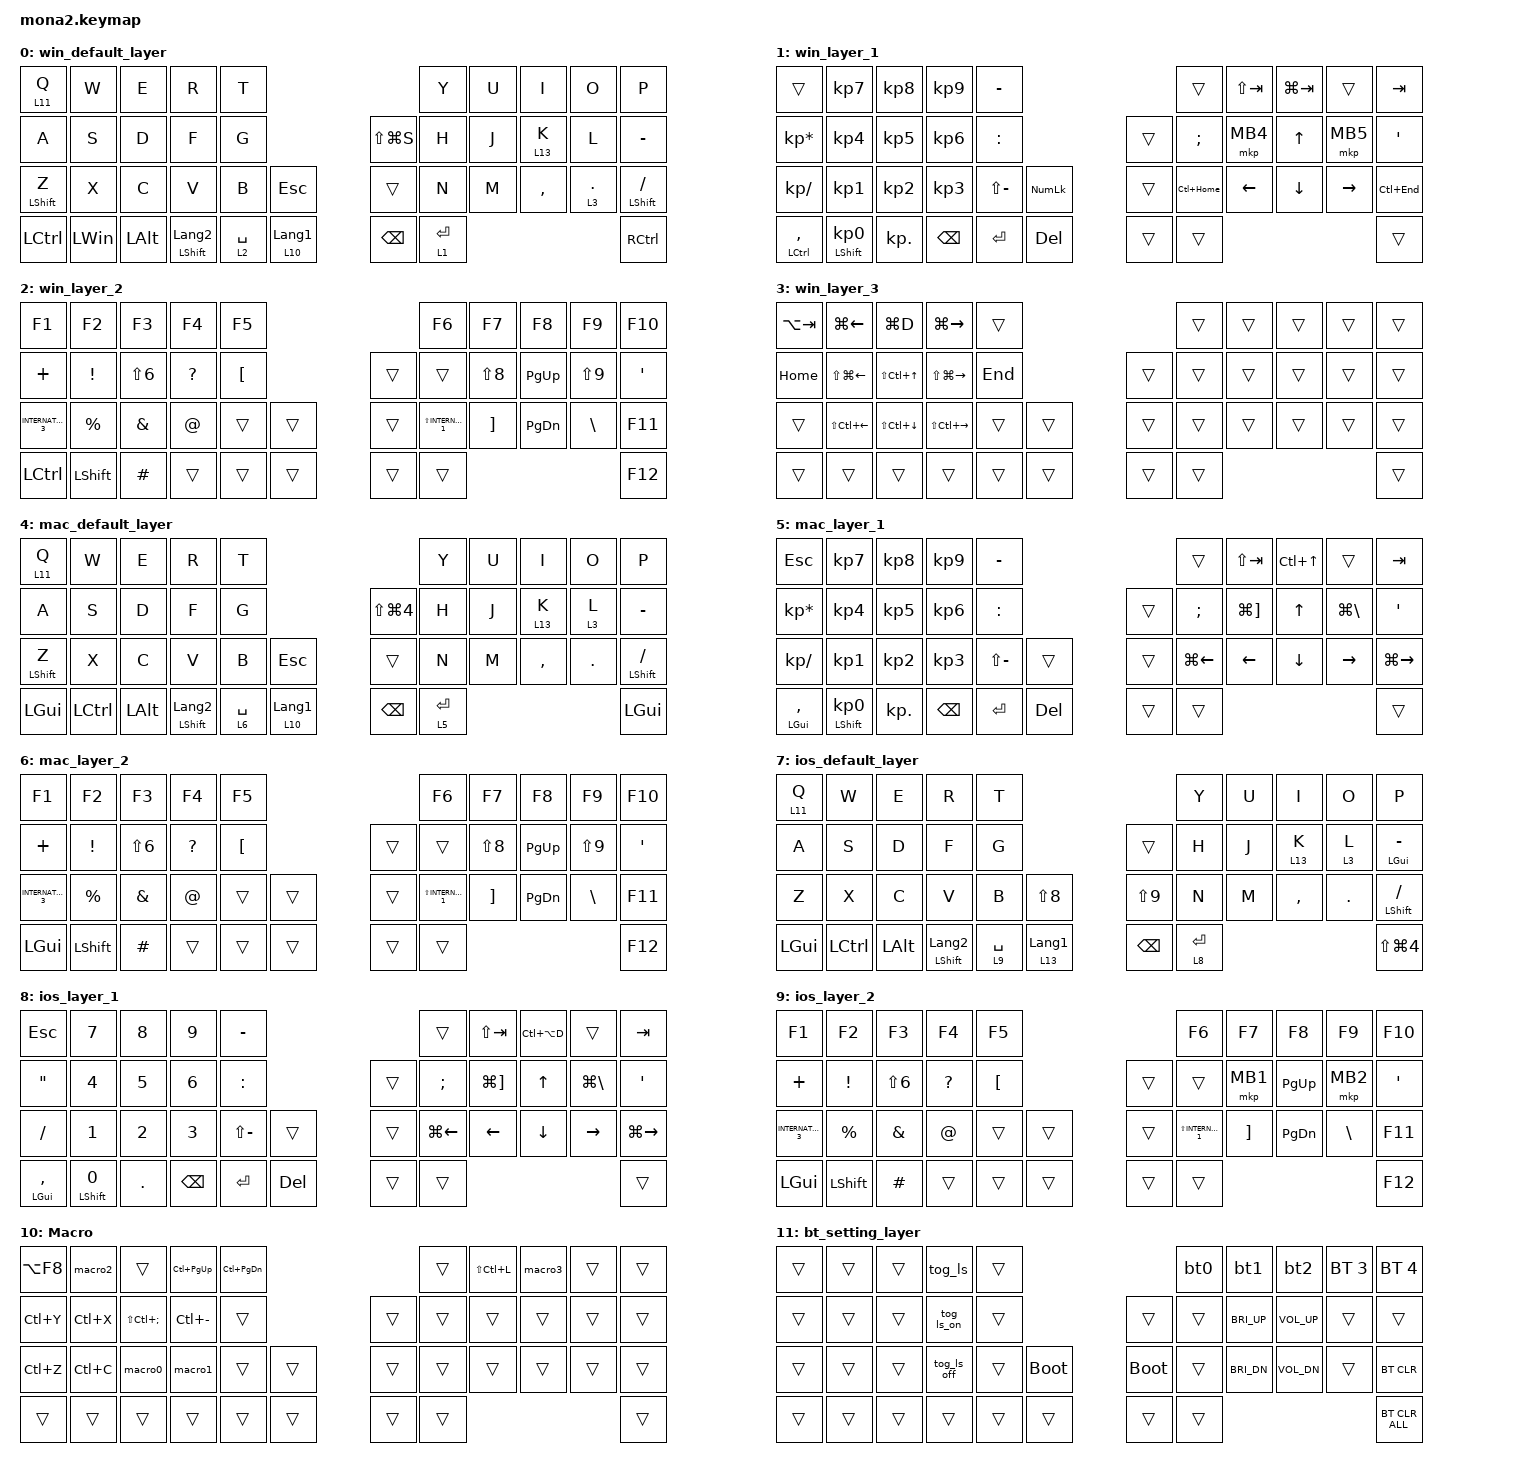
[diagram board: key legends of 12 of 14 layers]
#include <input/processors.dtsi>
#include <dt-bindings/zmk/input_transform.h>
#include <zephyr/dt-bindings/input/input-event-codes.h>
#include <behaviors.dtsi>
#include <dt-bindings/zmk/bt.h>
#include <dt-bindings/zmk/keys.h>
#include <dt-bindings/zmk/pointing.h>

#define ZMK_POINTING_DEFAULT_SCRL_VAL 100
#define MOUSE 12
#define SCROLL 13

&mt {
    flavor = "balanced";
    quick-tap-ms = <0>;
};

&lt {
    quick-tap-ms = <0>; // 初期設定は300
    flavor = "balanced";
};

&mkp_input_listener { input-processors = <&zip_temp_layer 12 250>; };

/ {
    combos {
        compatible = "zmk,combos";

        alt+ctrl+del {
            bindings = <&kp LA(LC(DELETE))>;
            key-positions = <9 40>;
        };

        left_click {
            bindings = <&mkp LCLK>;
            key-positions = <18 17>;
        };

        right_click {
            bindings = <&mkp RCLK>;
            key-positions = <19 18>;
        };

        caps_word {
            bindings = <&caps_word>;
            key-positions = <38 39>;
        };
    };

    macros {
        to_layer_0: to_layer_0 {
            compatible = "zmk,behavior-macro-one-param";
            #binding-cells = <1>;
            bindings = <&to 0 &macro_param_1to1 &kp MACRO_PLACEHOLDER>;
            label = "TO_LAYER_0";
        };

        macro0: macro0 {
            compatible = "zmk,behavior-macro";
            #binding-cells = <0>;
            bindings = <&kp LA(LC(V)) &kp V &kp ENTER>;
            label = "MACRO0";
        };

        macro1: macro1 {
            compatible = "zmk,behavior-macro";
            #binding-cells = <0>;
            bindings = <&kp LA(H) &kp M &kp C &kp ENTER>;
            label = "MACRO1";
        };

        macro2: macro2 {
            compatible = "zmk,behavior-macro";
            #binding-cells = <0>;
            bindings = <&kp LC(G) &kp LA(S) &kp K &kp ENTER>;
            label = "MACRO2";
        };

        macro3: macro3 {
            compatible = "zmk,behavior-macro";
            #binding-cells = <0>;
            bindings = <&kp LEFT_ALT &kp D &kp F &kp S>;
            label = "MACRO3";
        };

        macro4_copy_lay15: macro_4 {
            compatible = "zmk,behavior-macro";
            #binding-cells = <0>;
            bindings = <&kp LS(LC(DOWN_ARROW)) &kp LS(LC(RIGHT_ARROW)) &kp LS(LC(RIGHT_ARROW)) &kp LC(C)>;
            label = "MACRO_4";
        };

        macro_5_copy_lay15: macro_5 {
            compatible = "zmk,behavior-macro";
            #binding-cells = <0>;
            bindings = <&kp LS(LC(RIGHT_ARROW)) &kp LS(LC(RIGHT_ARROW)) &kp LC(C)>;
            label = "MACRO_5";
        };

        macro_6_ketsugou_lay15: macro_6 {
            compatible = "zmk,behavior-macro";
            #binding-cells = <0>;
            bindings = <&kp LS(LC(DOWN_ARROW)) &kp LA(H) &kp M &kp C &kp ENTER>;
            label = "MACRO_6";
        };

        bt0: bt0 {
            compatible = "zmk,behavior-macro";
            #binding-cells = <0>;
            bindings =
                <&tog_off 4 &tog_off 7>,
                <&macro_wait_time 200>,
                <&bt BT_SEL 0>,
                <&macro_wait_time 500>,
                <&tog_on 0 &bt BT_DISC 1 &bt BT_DISC 2>;

            label = "BT0";
        };

        bt1: bt1 {
            compatible = "zmk,behavior-macro";
            #binding-cells = <0>;
            bindings =
                <&tog_off 0 &tog_off 4 &tog_off 7>,
                <&macro_wait_time 200>,
                <&bt BT_SEL 1>,
                <&macro_wait_time 500>,
                <&tog_on 4 &bt BT_DISC 0 &bt BT_DISC 2>;

            label = "BT1";
        };

        bt2: bt2 {
            compatible = "zmk,behavior-macro";
            #binding-cells = <0>;
            bindings =
                <&tog_off 0 &tog_off 4 &tog_off 7>,
                <&macro_wait_time 200>,
                <&bt BT_SEL 2>,
                <&macro_wait_time 500>,
                <&tog_on 7 &bt BT_DISC 0 &bt BT_DISC 1>;

            label = "BT2";
        };

        exit_AML: exit_AML {
            compatible = "zmk,behavior-macro";
            wait-ms = <0>;
            tap-ms = <0>;
            #binding-cells = <0>;
            bindings = <&tog_off MOUSE>;
            label = "exit_AML";
        };

        kp_exit_AML: kp_exit_AML {
            compatible = "zmk,behavior-macro-one-param";
            wait-ms = <0>;
            tap-ms = <0>;
            #binding-cells = <1>;
            bindings = <&macro_param_1to1 &kp MACRO_PLACEHOLDER &exit_AML>;
            label = "KP_exit_AML";
        };
    };

    behaviors {
        lt_to_layer_0: lt_to_layer_0 {
            compatible = "zmk,behavior-hold-tap";
            label = "LAYER_TAP_TO_0";
            bindings = <&mo>, <&to_layer_0>;

            #binding-cells = <2>;
            tapping-term-ms = <200>;
        };

        encoder_msc: sensor_rotate_msc {
            compatible = "zmk,behavior-sensor-rotate-var";
            #sensor-binding-cells = <2>;
            bindings = <&msc>, <&msc>;

            tap-ms = <50>;
        };

        scroll_up_down: mouse_wheel_up_down {
            compatible = "zmk,behavior-sensor-rotate";
            #sensor-binding-cells = <0>;
            bindings = <&msc SCRL_DOWN>, <&msc SCRL_UP>;

            tap-ms = <15>;
        };

        scroll_right_left: mouse_wheel_right_left {
            compatible = "zmk,behavior-sensor-rotate";
            #sensor-binding-cells = <0>;
            bindings = <&msc SCRL_LEFT>, <&msc SCRL_RIGHT>;

            tap-ms = <15>;
        };

        mt_exit_AML_on_tap: mt_exit_AML_on_tap {
            compatible = "zmk,behavior-hold-tap";
            label = "MT_exit_AML_ON_TAP";
            bindings = <&kp>, <&kp_exit_AML>;

            #binding-cells = <2>;
            tapping-term-ms = <250>;
            flavor = "tap-preferred";
            quick-tap-ms = <200>;
        };

        tog_on: toggle_layer_on_only {
            compatible = "zmk,behavior-toggle-layer";
            #binding-cells = <1>;
            display-name = "Toggle Layer On";
            toggle-mode = "on";
        };

        tog_off: toggle_layer_off_only {
            compatible = "zmk,behavior-toggle-layer";
            #binding-cells = <1>;
            display-name = "Toggle Layer Off";
            toggle-mode = "off";
        };

        // Keep the original key_press behavior for ZMK core components

        original_key_press: original_key_press {
            compatible = "zmk,behavior-key-press";
            #binding-cells = <1>;
            label = "KEY_PRESS";
        };

        // Override the existing &kp behavior to use our custom implementation

        kp: key_press {
            compatible = "zmk,behavior-layout-shift-key-press";
            #binding-cells = <1>;
            label = "LAYOUT_SHIFT_KEY_PRESS";
        };

        // Layout shift toggle behaviors

        tog_ls: toggle_layout_shift {
            compatible = "zmk,behavior-layout-shift-toggle";
            #binding-cells = <0>;
            toggle-mode = "flip";
            label = "LAYOUT_SHIFT_TOGGLE";
        };

        tog_ls_on: toggle_layout_shift_on {
            compatible = "zmk,behavior-layout-shift-toggle";
            #binding-cells = <0>;
            toggle-mode = "on";
            label = "LAYOUT_SHIFT_TOGGLE_ON";
        };

        tog_ls_off: toggle_layout_shift_off {
            compatible = "zmk,behavior-layout-shift-toggle";
            #binding-cells = <0>;
            toggle-mode = "off";
            label = "LAYOUT_SHIFT_TOGGLE_OFF";
        };
    };

    keymap {
        compatible = "zmk,keymap";

        win_default_layer {
            bindings = <
&lt 11 Q                          &kp W         &kp E         &kp R                                      &kp T                                                       &kp Y        &kp U  &kp I      &kp O      &kp P
&kp A                             &kp S         &kp D         &kp F                                      &kp G                                        &kp LS(LG(S))  &kp H        &kp J  &lt 13 K   &kp L      &kp MINUS
&mt_exit_AML_on_tap LEFT_SHIFT Z  &kp X         &kp C         &kp V                                      &kp B        &kp ESCAPE                      &trans         &kp N        &kp M  &kp COMMA  &lt 3 DOT  &mt LEFT_SHIFT SLASH
&kp LCTRL                         &kp LEFT_WIN  &kp LEFT_ALT  &mt_exit_AML_on_tap LEFT_SHIFT LANGUAGE_2  &lt 2 SPACE  &lt_to_layer_0 10 LANGUAGE_1    &kp BACKSPACE  &lt 1 ENTER                               &kp RCTRL
            >;

            sensor-bindings = <&encoder_msc SCRL_DOWN SCRL_UP>;
        };

        win_layer_1 {
            bindings = <
&trans           &kp KP_NUMBER_7       &kp KP_N8   &kp KP_NUMBER_9  &kp MINUS                            &trans         &kp LS(TAB)     &kp LG(TAB)     &trans           &kp TAB
&kp KP_MULTIPLY  &kp KP_NUMBER_4       &kp KP_N5   &kp KP_NUMBER_6  &kp COLON                    &trans  &kp SEMICOLON  &mkp MB4        &kp UP_ARROW    &mkp MB5         &kp SINGLE_QUOTE
&kp KP_SLASH     &kp KP_N1             &kp KP_N2   &kp KP_N3        &kp LS(MINUS)  &kp KP_NUM    &trans  &kp LC(HOME)   &kp LEFT_ARROW  &kp DOWN_ARROW  &kp RIGHT_ARROW  &kp LC(END)
&mt LCTRL COMMA  &mt LEFT_SHIFT KP_N0  &kp KP_DOT  &kp BACKSPACE    &kp ENTER      &kp DEL       &trans  &trans                                                          &trans
            >;

            sensor-bindings = <&encoder_msc SCRL_LEFT SCRL_RIGHT>;
        };

        win_layer_2 {
            bindings = <
&kp F1               &kp F2          &kp F3            &kp F4        &kp F5                              &kp F6                   &kp F7             &kp F8         &kp F9         &kp F10
&kp PLUS             &kp EXCL        &kp LS(NUMBER_6)  &kp QUESTION  &kp LEFT_BRACKET            &trans  &trans                   &kp LS(N8)         &kp PAGE_UP    &kp LS(N9)     &kp SINGLE_QUOTE
&kp INTERNATIONAL_3  &kp PERCENT     &kp AMPERSAND     &kp AT_SIGN   &trans            &trans    &trans  &kp LS(INTERNATIONAL_1)  &kp RIGHT_BRACKET  &kp PAGE_DOWN  &kp BACKSLASH  &kp F11
&kp LCTRL            &kp LEFT_SHIFT  &kp HASH          &trans        &trans            &trans    &trans  &trans                                                                    &kp F12
            >;

            sensor-bindings = <&encoder_msc SCRL_DOWN SCRL_UP>;
        };

        win_layer_3 {
            bindings = <
&kp LA(TAB)  &kp LG(LEFT_ARROW)      &kp LG(D)               &kp LG(RIGHT_ARROW)      &trans                     &trans  &trans  &trans  &trans  &trans
&kp HOME     &kp LS(LG(LEFT_ARROW))  &kp LS(LC(UP_ARROW))    &kp LS(LG(RIGHT_ARROW))  &kp END            &trans  &trans  &trans  &trans  &trans  &trans
&trans       &kp LS(LC(LEFT_ARROW))  &kp LS(LC(DOWN_ARROW))  &kp LS(LC(RIGHT_ARROW))  &trans   &trans    &trans  &trans  &trans  &trans  &trans  &trans
&trans       &trans                  &trans                  &trans                   &trans   &trans    &trans  &trans                          &trans
            >;

            sensor-bindings = <&inc_dec_kp C_VOL_DN C_VOL_UP>;
        };

        mac_default_layer {
            bindings = <
&lt 11 Q                          &kp W      &kp E         &kp R                                      &kp T                                                   &kp Y        &kp U  &kp I      &kp O    &kp P
&kp A                             &kp S      &kp D         &kp F                                      &kp G                             &kp LS(LG(NUMBER_4))  &kp H        &kp J  &lt 13 K   &lt 3 L  &kp MINUS
&mt_exit_AML_on_tap LEFT_SHIFT Z  &kp X      &kp C         &kp V                                      &kp B        &kp ESC              &trans                &kp N        &kp M  &kp COMMA  &kp DOT  &mt LEFT_SHIFT SLASH
&kp LEFT_GUI                      &kp LCTRL  &kp LEFT_ALT  &mt_exit_AML_on_tap LEFT_SHIFT LANGUAGE_2  &lt 6 SPACE  &lt 10 LANGUAGE_1    &kp BACKSPACE         &lt 5 ENTER                             &kp LEFT_GUI
            >;

            sensor-bindings = <&encoder_msc SCRL_DOWN SCRL_UP>;
        };

        mac_layer_1 {
            bindings = <
&kp ESC             &kp KP_NUMBER_7       &kp KP_N8   &kp KP_NUMBER_9  &kp MINUS                            &trans              &kp LS(TAB)            &kp LC(UP_ARROW)  &trans             &kp TAB
&kp KP_MULTIPLY     &kp KP_NUMBER_4       &kp KP_N5   &kp KP_NUMBER_6  &kp COLON                    &trans  &kp SEMICOLON       &kp LG(RIGHT_BRACKET)  &kp UP_ARROW      &kp LG(BACKSLASH)  &kp SINGLE_QUOTE
&kp KP_SLASH        &kp KP_N1             &kp KP_N2   &kp KP_N3        &kp LS(MINUS)  &trans        &trans  &kp LG(LEFT_ARROW)  &kp LEFT_ARROW         &kp DOWN_ARROW    &kp RIGHT_ARROW    &kp LG(RIGHT_ARROW)
&mt LEFT_GUI COMMA  &mt LEFT_SHIFT KP_N0  &kp KP_DOT  &kp BACKSPACE    &kp ENTER      &kp DELETE    &trans  &trans                                                                          &trans
            >;

            sensor-bindings = <&encoder_msc SCRL_LEFT SCRL_RIGHT>;
        };

        mac_layer_2 {
            bindings = <
&kp F1               &kp F2          &kp F3            &kp F4        &kp F5                              &kp F6                   &kp F7             &kp F8         &kp F9         &kp F10
&kp PLUS             &kp EXCL        &kp LS(NUMBER_6)  &kp QUESTION  &kp LEFT_BRACKET            &trans  &trans                   &kp LS(N8)         &kp PAGE_UP    &kp LS(N9)     &kp SINGLE_QUOTE
&kp INTERNATIONAL_3  &kp PERCENT     &kp AMPERSAND     &kp AT_SIGN   &trans            &trans    &trans  &kp LS(INTERNATIONAL_1)  &kp RIGHT_BRACKET  &kp PAGE_DOWN  &kp BACKSLASH  &kp F11
&kp LEFT_GUI         &kp LEFT_SHIFT  &kp HASH          &trans        &trans            &trans    &trans  &trans                                                                    &kp F12
            >;

            sensor-bindings = <&encoder_msc SCRL_DOWN SCRL_UP>;
        };

        ios_default_layer {
            bindings = <
&lt 11 Q      &kp W      &kp E         &kp R                                      &kp T                                            &kp Y        &kp U  &kp I      &kp O       &kp P
&kp A         &kp S      &kp D         &kp F                                      &kp G                             &trans         &kp H        &kp J  &lt 13 K   &lt 3 L     &mt LEFT_GUI MINUS
&kp Z         &kp X      &kp C         &kp V                                      &kp B        &kp LS(N8)           &kp LS(N9)     &kp N        &kp M  &kp COMMA  &kp PERIOD  &mt LEFT_SHIFT SLASH
&kp LEFT_GUI  &kp LCTRL  &kp LEFT_ALT  &mt_exit_AML_on_tap LEFT_SHIFT LANGUAGE_2  &lt 9 SPACE  &lt 13 LANGUAGE_1    &kp BACKSPACE  &lt 8 ENTER                                &kp LS(LG(NUMBER_4))
            >;

            sensor-bindings = <&encoder_msc SCRL_DOWN SCRL_UP>;
        };

        ios_layer_1 {
            bindings = <
&kp ESC             &kp N7             &kp N8        &kp N9         &kp MINUS                            &trans              &kp LS(TAB)            &kp LC(LA(D))   &trans             &kp TAB
&kp DOUBLE_QUOTES   &kp NUMBER_4       &kp N5        &kp NUMBER_6   &kp COLON                    &trans  &kp SEMICOLON       &kp LG(RIGHT_BRACKET)  &kp UP_ARROW    &kp LG(BACKSLASH)  &kp SINGLE_QUOTE
&kp SLASH           &kp N1             &kp NUMBER_2  &kp NUMBER_3   &kp LS(MINUS)  &trans        &trans  &kp LG(LEFT_ARROW)  &kp LEFT_ARROW         &kp DOWN_ARROW  &kp RIGHT_ARROW    &kp LG(RIGHT_ARROW)
&mt LEFT_GUI COMMA  &mt LEFT_SHIFT N0  &kp DOT       &kp BACKSPACE  &kp ENTER      &kp DELETE    &trans  &trans                                                                        &trans
            >;

            sensor-bindings = <&encoder_msc SCRL_LEFT SCRL_RIGHT>;
        };

        ios_layer_2 {
            bindings = <
&kp F1               &kp F2          &kp F3            &kp F4        &kp F5                              &kp F6                   &kp F7             &kp F8         &kp F9         &kp F10
&kp PLUS             &kp EXCL        &kp LS(NUMBER_6)  &kp QUESTION  &kp LEFT_BRACKET            &trans  &trans                   &mkp MB1           &kp PAGE_UP    &mkp MB2       &kp SINGLE_QUOTE
&kp INTERNATIONAL_3  &kp PERCENT     &kp AMPERSAND     &kp AT_SIGN   &trans            &trans    &trans  &kp LS(INTERNATIONAL_1)  &kp RIGHT_BRACKET  &kp PAGE_DOWN  &kp BACKSLASH  &kp F11
&kp LEFT_GUI         &kp LEFT_SHIFT  &kp HASH          &trans        &trans            &trans    &trans  &trans                                                                    &kp F12
            >;

            sensor-bindings = <&encoder_msc SCRL_DOWN SCRL_UP>;
        };

        Macro {
            bindings = <
&kp LA(F8)  &macro2    &trans                 &kp LC(PAGE_UP)  &kp LC(PAGE_DOWN)                    &trans  &kp LS(LC(L))  &macro3  &trans  &trans
&kp LC(Y)   &kp LC(X)  &kp LS(LC(SEMICOLON))  &kp LC(MINUS)    &trans                       &trans  &trans  &trans         &trans   &trans  &trans
&kp LC(Z)   &kp LC(C)  &macro0                &macro1          &trans             &trans    &trans  &trans  &trans         &trans   &trans  &trans
&trans      &trans     &trans                 &trans           &trans             &trans    &trans  &trans                                  &trans
            >;
        };

        bt_setting_layer {
            bindings = <
&trans  &trans  &trans  &tog_ls      &trans                              &bt0    &bt1          &bt2             &bt BT_SEL 3  &bt BT_SEL 4
&trans  &trans  &trans  &tog_ls_on   &trans                 &trans       &trans  &kp C_BRI_UP  &kp C_VOLUME_UP  &trans        &trans
&trans  &trans  &trans  &tog_ls_off  &trans  &bootloader    &bootloader  &trans  &kp C_BRI_DN  &kp C_VOL_DN     &trans        &bt BT_CLR
&trans  &trans  &trans  &trans       &trans  &trans         &trans       &trans                                               &bt BT_CLR_ALL
            >;

            sensor-bindings = <&encoder_msc SCRL_DOWN SCRL_UP>;
        };

        MOUSE {
            bindings = <
&trans  &trans  &trans  &trans  &trans                    &trans  &trans  &trans  &trans     &trans
&trans  &trans  &trans  &trans  &trans            &trans  &trans  &trans  &trans  &mkp RCLK  &mkp LCLK
&trans  &trans  &trans  &trans  &trans  &trans    &trans  &trans  &trans  &trans  &trans     &trans
&trans  &trans  &trans  &trans  &trans  &trans    &trans  &trans                             &trans
            >;

            sensor-bindings = <&encoder_msc SCRL_DOWN SCRL_UP>;
        };

        SCROLL {
            bindings = <
&trans  &trans  &trans  &trans  &trans                    &trans  &trans  &trans  &trans  &trans
&trans  &trans  &trans  &trans  &trans            &trans  &trans  &trans  &trans  &trans  &trans
&trans  &trans  &trans  &trans  &trans  &trans    &trans  &trans  &trans  &trans  &trans  &trans
&trans  &trans  &trans  &trans  &trans  &trans    &trans  &trans                          &trans
            >;

            sensor-bindings = <&encoder_msc SCRL_DOWN SCRL_UP>;
        };
    };
};
